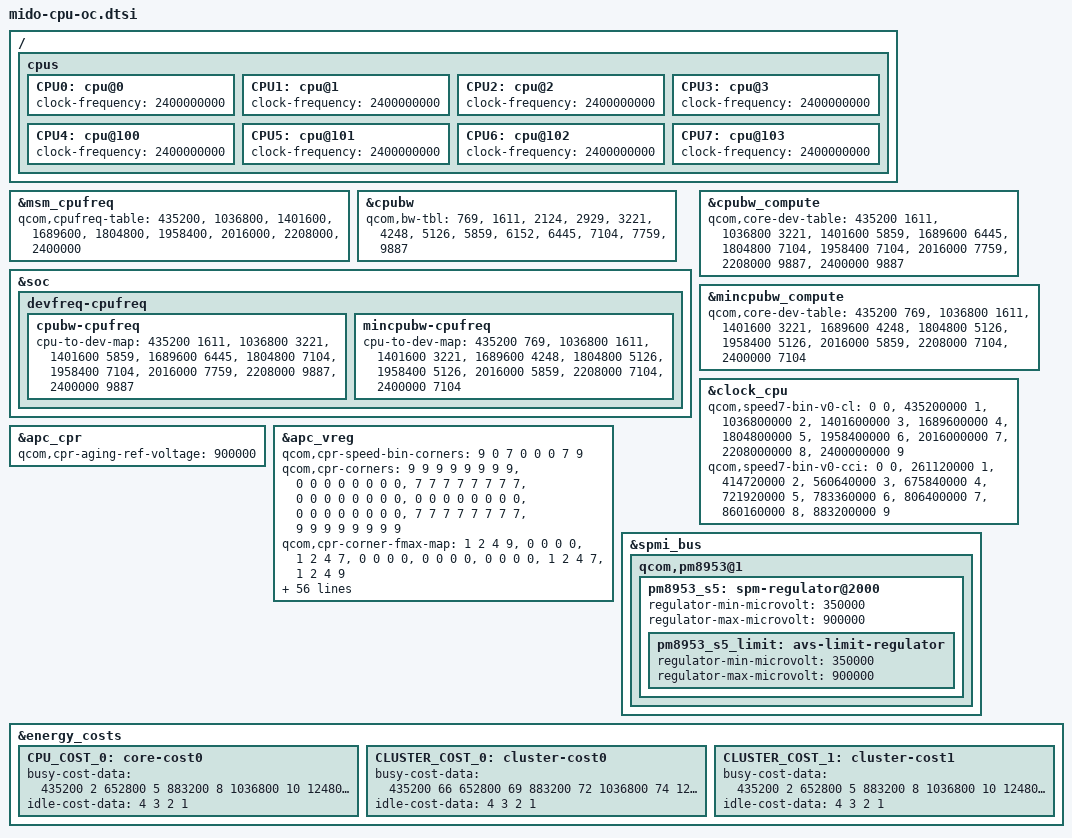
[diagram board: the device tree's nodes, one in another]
/* Copyright (c) 2020, The Linux Foundation. All rights reserved.
*  Copyright (c) 2020, Jebaitedneko.
*
* This program is free software; you can redistribute it and/or modify
* it under the terms of the GNU General Public License version 2 and
* only version 2 as published by the Free Software Foundation.
*
* This program is distributed in the hope that it will be useful,
* but WITHOUT ANY WARRANTY; without even the implied warranty of
* MERCHANTABILITY or FITNESS FOR A PARTICULAR PURPOSE.  See the
* GNU General Public License for more details.
*/

/ {

	cpus {

		CPU0: cpu@0 {
			clock-frequency = <2400000000>;
		};
		CPU1: cpu@1 {
			clock-frequency = <2400000000>;
		};
		CPU2: cpu@2 {
			clock-frequency = <2400000000>;
		};
		CPU3: cpu@3 {
			clock-frequency = <2400000000>;
		};
		CPU4: cpu@100 {
			clock-frequency = <2400000000>;
		};
		CPU5: cpu@101 {
			clock-frequency = <2400000000>;
		};
		CPU6: cpu@102 {
			clock-frequency = <2400000000>;
		};
		CPU7: cpu@103 {
			clock-frequency = <2400000000>;
		};
	};
};

&msm_cpufreq {

	qcom,cpufreq-table =
		<  435200 >,
		< 1036800 >,
		< 1401600 >,
		< 1689600 >,
		< 1804800 >,
		< 1958400 >,
		< 2016000 >,
		< 2208000 >,
		< 2400000 >;
};

&cpubw {

	qcom,bw-tbl =
		<   769 /*  100.8 MHz  */ >,
		<  1611 /*  211.2 MHz  */ >,
		<  2124 /*  278.4 MHz  */ >,
		<  2929 /*  384   MHz  */ >,
		<  3221 /*  422.4 MHz  */ >,
		<  4248 /*  556.8 MHz  */ >,
		<  5126 /*  672   MHz  */ >,
		<  5859 /*  768   MHz  */ >,
		<  6152 /*  806.4 MHz  */ >,
		<  6445 /*  844.8 MHz  */ >,
		<  7104 /*  931.2 MHz  */ >,
		<  7759 /*  1017.0 MHz */ >,
		<  9887 /*  1296.0 MHz */ >;
};

&soc {

	devfreq-cpufreq {

		cpubw-cpufreq {

			cpu-to-dev-map =
				<  435200  1611>,
				< 1036800  3221>,
				< 1401600  5859>,
				< 1689600  6445>,
				< 1804800  7104>,
				< 1958400  7104>,
				< 2016000  7759>,
				< 2208000  9887>,
				< 2400000  9887>;
		};

		mincpubw-cpufreq {

			cpu-to-dev-map =
				<  435200  769>,
				< 1036800  1611>,
				< 1401600  3221>,
				< 1689600  4248>,
				< 1804800  5126>,
				< 1958400  5126>,
				< 2016000  5859>,
				< 2208000  7104>,
				< 2400000  7104>;
		};
	};
};

&cpubw_compute {

	qcom,core-dev-table =
		<  435200  1611>,
		< 1036800  3221>,
		< 1401600  5859>,
		< 1689600  6445>,
		< 1804800  7104>,
		< 1958400  7104>,
		< 2016000  7759>,
		< 2208000  9887>,
		< 2400000  9887>;
};

&mincpubw_compute {

	qcom,core-dev-table =
		<  435200  769>,
		< 1036800  1611>,
		< 1401600  3221>,
		< 1689600  4248>,
		< 1804800  5126>,
		< 1958400  5126>,
		< 2016000  5859>,
		< 2208000  7104>,
		< 2400000  7104>;
};

&clock_cpu {
	qcom,speed7-bin-v0-cl =
		<          0 0>,
		<  435200000 1>,
		< 1036800000 2>,
		< 1401600000 3>,
		< 1689600000 4>,
		< 1804800000 5>,
		< 1958400000 6>,
		< 2016000000 7>,
		< 2208000000 8>,
		< 2400000000 9>;
	qcom,speed7-bin-v0-cci =
		<          0 0>,
		<  261120000 1>,
		<  414720000 2>,
		<  560640000 3>,
		<  675840000 4>,
		<  721920000 5>,
		<  783360000 6>,
		<  806400000 7>,
		<  860160000 8>,
		<  883200000 9>;
};

&apc_cpr {

	/* Turbo (corner 6) ceiling voltage */
	qcom,cpr-aging-ref-voltage = <900000>;
};

&apc_vreg {

	qcom,cpr-speed-bin-corners =
		<9 0 7 0 0 0 7 9>;

	qcom,cpr-corners =
		/* Speed bin 0 */
		<9 9 9 9 9 9 9 9>,

		/* Speed bin 1 */
		<0 0 0 0 0 0 0 0>,

		/* Speed bin 2 */
		<7 7 7 7 7 7 7 7>,

		/* Speed bin 3..5 */
		<0 0 0 0 0 0 0 0>,
		<0 0 0 0 0 0 0 0>,
		<0 0 0 0 0 0 0 0>,

		/* Speed bin 6 */
		<7 7 7 7 7 7 7 7>,

		/* Speed bin 7 */
		<9 9 9 9 9 9 9 9>;

	qcom,cpr-corner-fmax-map =
		/* Speed bin 0 */
		<1 2 4 9>,

		/* Speed bin 1 */
		<0 0 0 0>,

		/* Speed bin 2 */
		<1 2 4 7>,

		/* Speed bin 3..5 */
		<0 0 0 0>,
		<0 0 0 0>,
		<0 0 0 0>,

		/* Speed bin 6 */
		<1 2 4 7>,

		/* Speed bin 7 */
		<1 2 4 9>;

	qcom,cpr-voltage-ceiling =
		/* Speed bin 0 */
		<600000  700000 750000 800000 850000
			875000 875000 900000 900000>,

		/* Speed bin 2 */
		<600000  700000 750000 800000 850000
			875000 875000>,

		/* Speed bin 6 */
		<600000  700000 750000 800000 850000
			875000 875000>,

		/* Speed bin 7 */
		<600000  700000 750000 800000 850000
			875000 875000 900000 900000>;

	qcom,cpr-voltage-floor =
		/* Speed bin 0 */
		<350000  350000 350000 350000 350000
			350000  350000 350000 350000>,

		/* Speed bin 2 */
		<350000  350000 350000 350000 350000
			350000  350000>,

		/* Speed bin 6 */
		<350000  350000 350000 350000 350000
			350000  350000>,

		/* Speed bin 7 */
		<350000  350000 350000 350000 350000
			350000  350000 350000 350000>;

	qcom,cpr-floor-to-ceiling-max-range =
	/* Speed bin 0; CPR rev 0..7 */
		<    0     0     0     0     0
			0     0     0     0>,
		<300000 300000 300000 300000 300000
		300000 300000 300000 300000>,
		<300000 300000 300000 300000 300000
		300000 300000 300000 300000>,
		<300000 300000 300000 300000 300000
		300000 300000 300000 300000>,
		<300000 300000 300000 300000 300000
		300000 300000 300000 300000>,
		<300000 300000 300000 300000 300000
		300000 300000 300000 300000>,
		<300000 300000 300000 300000 300000
		300000 300000 300000 300000>,
		<300000 300000 300000 300000 300000
		300000 300000 300000 300000>,

	/* Speed bin 2; CPR rev 0..7 */
		<    0     0     0     0     0
			0     0>,
		<300000 300000 300000 300000 300000
		300000 300000>,
		<300000 300000 300000 300000 300000
		300000 300000>,
		<300000 300000 300000 300000 300000
		300000 300000>,
		<300000 300000 300000 300000 300000
		300000 300000>,
		<300000 300000 300000 300000 300000
		300000 300000>,
		<300000 300000 300000 300000 300000
		300000 300000>,
		<300000 300000 300000 300000 300000
		300000 300000>,

	/* Speed bin 6; CPR rev 0..7 */
		<    0     0     0     0     0
			0     0>,
		<300000 300000 300000 300000 300000
		300000 300000>,
		<300000 300000 300000 300000 300000
		300000 300000>,
		<300000 300000 300000 300000 300000
		300000 300000>,
		<300000 300000 300000 300000 300000
		300000 300000>,
		<300000 300000 300000 300000 300000
		300000 300000>,
		<300000 300000 300000 300000 300000
		300000 300000>,
		<300000 300000 300000 300000 300000
		300000 300000>,

	/* Speed bin 7; CPR rev 0..7 */
		<    0     0     0     0     0
			0     0     0     0>,
		<300000 300000 300000 300000 300000
		300000 300000 300000 300000>,
		<300000 300000 300000 300000 300000
		300000 300000 300000 300000>,
		<300000 300000 300000 300000 300000
		300000 300000 300000 300000>,
		<300000 300000 300000 300000 300000
		300000 300000 300000 300000>,
		<300000 300000 300000 300000 300000
		300000 300000 300000 300000>,
		<300000 300000 300000 300000 300000
		300000 300000 300000 300000>,
		<300000 300000 300000 300000 300000
		300000 300000 300000 300000>;

	qcom,cpr-misc-fuse-voltage-adjustment =
		/* Speed bin 0; misc fuse 0..1 */
		<    0     0     0     0      0
				0     0     0     0>,
		<    0     0 30000     0      0
				0     0     0     0>,

		/* Speed bin 2; misc fuse 0..1 */
		<    0     0     0     0      0
				0     0>,
		<    0     0 30000     0      0
				0     0>,

		/* Speed bin 6; misc fuse 0..1 */
		<    0     0     0     0      0
				0     0>,
		<    0     0 30000     0      0
				0     0>,

		/* Speed bin 7; misc fuse 0..1 */
		<    0     0     0     0      0
				0     0     0     0>,
		<    0     0 30000     0      0
				0     0     0     0>;

	qcom,mem-acc-voltage =
		/* Speed bin 0 */
		<1 1 2 2 2 2 2 2 2>,

		/* Speed bin 2 */
		<1 1 2 2 2 2 2>,

		/* Speed bin 6 */
		<1 1 2 2 2 2 2>,

		/* Speed bin 7 */
		<1 1 2 2 2 2 2 2 2>;

	qcom,corner-frequencies =
		/* Speed bin 0 */
		<435200000 1036800000 1401600000
		1689600000 1804800000 1958400000
		2016000000 2208000000 2400000000>,

		/* Speed bin 2 */
		<435200000 1036800000 1401600000
		1689600000 1804800000 1958400000
		2016000000>,

		/* Speed bin 6 */
		<435200000 1036800000 1401600000
		1689600000 1804800000 1958400000
		2016000000>,

		/* Speed bin 7 */
		<435200000 1036800000 1401600000
		1689600000 1804800000 1958400000
		2016000000 2208000000 2400000000>;
};

&spmi_bus {
	qcom,pm8953@1 {

		/* PM8953 S5 + S6 = VDD_APC supply */
		pm8953_s5: spm-regulator@2000 {
			regulator-min-microvolt = <350000>; /* Default 400000 */
			regulator-max-microvolt = <900000>; /* Default 1140000 */

			pm8953_s5_limit: avs-limit-regulator {
				regulator-min-microvolt = <350000>; /* Default 400000 */
				regulator-max-microvolt = <900000>; /* Default 1140000 */
			};
		};
	};
};

&energy_costs {

	CPU_COST_0: core-cost0 {

		busy-cost-data = <
			435200   2
			652800   5
			883200   8
			1036800  10
			1248000  13
			1401600  16
			1536000  19
			1689600  22
			1804800  26
			1843200  27
			1958400  33
			2016000  36
			2150400  43
			2208000  44
			2304000  54
			2400000  65
		>;
		idle-cost-data = <
			4 3 2 1
		>;
	};

	CLUSTER_COST_0: cluster-cost0 {

		busy-cost-data = <
			435200   66
			652800   69
			883200   72
			1036800   74
			1248000   77
			1401600   80
			1536000   90
			1689600  100
			1804800  110
			1843200  120
			1958400  130
			2016000  140
			2150400  150
			2208000  160
			2304000  170
			2400000  180
		>;
		idle-cost-data = <
			4 3 2 1
		>;
	};

	CLUSTER_COST_1: cluster-cost1 {

		busy-cost-data = <
			435200    2
			652800    5
			883200    8
			1036800   10
			1248000   13
			1401600   16
			1536000   85
			1689600   95
			1804800  105
			1843200  115
			1958400  125
			2016000  135
			2150400  145
			2208000  155
			2304000  165
			2400000  175
		>;
		idle-cost-data = <
			4 3 2 1
		>;
	};
};
